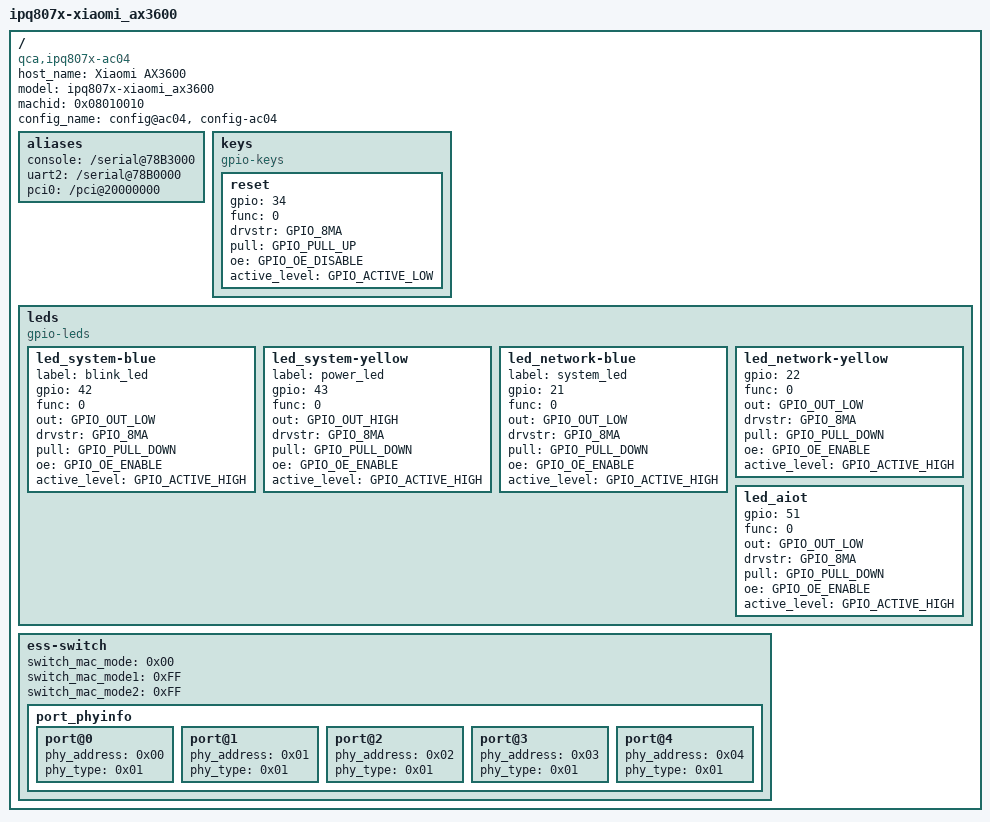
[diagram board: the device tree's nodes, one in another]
/*
 * Copyright (c) 2016 - 2018, The Linux Foundation. All rights reserved.
 *
 * This program is free software; you can redistribute it and/or modify
 * it under the terms of the GNU General Public License version 2 and
 * only version 2 as published by the Free Software Foundation.
 *
 * This program is distributed in the hope that it will be useful,
 * but WITHOUT ANY WARRANTY; without even the implied warranty of
 * MERCHANTABILITY or FITNESS FOR A PARTICULAR PURPOSE.  See the
 * GNU General Public License for more details.
 */

/dts-v1/;
#include "ipq807x-soc.dtsi"
#include <dt-bindings/qcom/gpio-ipq807x.h>
/ {
    host_name = "Xiaomi AX3600";
	model = "ipq807x-xiaomi_ax3600";
	compatible = "qca,ipq807x-ac04", "qca,ipq807x";
	machid = <0x08010010>;
	config_name = "config@ac04", "config-ac04";

	aliases {
		console = "/serial@78B3000";
		uart2 = "/serial@78B0000";
		pci0 = "/pci@20000000";
	};

    keys {
		compatible = "gpio-keys";

        reset {
            gpio = <34>;
            func = <0>;
            drvstr = <GPIO_8MA>;
            pull = <GPIO_PULL_UP>;
            oe = <GPIO_OE_DISABLE>;
			active_level = <GPIO_ACTIVE_LOW>;
        };
    };

    leds {
		compatible = "gpio-leds";

		led_system-blue {
			label = "blink_led";
			gpio = <42>;
			func = <0>;
			out = <GPIO_OUT_LOW>;
			drvstr = <GPIO_8MA>;
			pull = <GPIO_PULL_DOWN>;
			oe = <GPIO_OE_ENABLE>;
            active_level = <GPIO_ACTIVE_HIGH>;
		};

		led_system-yellow {
			label = "power_led";
			gpio = <43>;
			func = <0>;
			out = <GPIO_OUT_HIGH>;
			drvstr = <GPIO_8MA>;
			pull = <GPIO_PULL_DOWN>;
			oe = <GPIO_OE_ENABLE>;
            active_level = <GPIO_ACTIVE_HIGH>;
		};

		led_network-blue {
			label = "system_led";
			gpio = <21>;
			func = <0>;
			out = <GPIO_OUT_LOW>;
			drvstr = <GPIO_8MA>;
			pull = <GPIO_PULL_DOWN>;
			oe = <GPIO_OE_ENABLE>;
            active_level = <GPIO_ACTIVE_HIGH>;
		};

		led_network-yellow {
			gpio = <22>;
			func = <0>;
			out = <GPIO_OUT_LOW>;
			drvstr = <GPIO_8MA>;
			pull = <GPIO_PULL_DOWN>;
			oe = <GPIO_OE_ENABLE>;
            active_level = <GPIO_ACTIVE_HIGH>;
		};

		led_aiot {
			gpio = <51>;
			func = <0>;
			out = <GPIO_OUT_LOW>;
			drvstr = <GPIO_8MA>;
			pull = <GPIO_PULL_DOWN>;
			oe = <GPIO_OE_ENABLE>;
            active_level = <GPIO_ACTIVE_HIGH>;
		};
    };

	ess-switch {
		switch_mac_mode = <0x00>;
		switch_mac_mode1 = <0xFF>;
		switch_mac_mode2 = <0xFF>;
		port_phyinfo {
			port@0 {
				phy_address = <0x00>;
				phy_type = <0x01>;
			};
			port@1 {
				phy_address = <0x01>;
				phy_type = <0x01>;
			};
			port@2 {
				phy_address = <0x02>;
				phy_type = <0x01>;
			};
			port@3 {
				phy_address = <0x03>;
				phy_type = <0x01>;
			};
			port@4 {
				phy_address = <0x04>;
				phy_type = <0x01>;
			};
		};
	};
};
